# M2003 register map
File version: 1.0
Registers are 32-bit, read-write, reset 0x0 unless marked. A register's access mark holds for its fields unless they carry their own. Offsets are from the block's base; [hi:lo] are bit positions; {n}, {i} and the like mark numbered series; 'fields as' and 'values as' point back to an identical list.

## ECAP0 — ECAP Register Map
Base 0x400B4000
0x00 ECAP_CNT — Input Capture Counter (24-bit Up Counter)
  [23:0] CNT — Input Capture Timer/Counter. The input Capture Timer/Counter is a 24-bit up-counting counter. The clock source for the counter is from the clock divider.
{0x4+4i} ECAP_HLD{i} (i=0..2) — Input Capture Hold Register {i}
  [23:0] HOLD — Input Capture Counter Hold Register. When an active input capture channel detects a valid edge signal change, the ECAPCNT value is latched into the corresponding holding register. Each input channel has its own holding register named by ECAP_HLDx where x is from 0 to 2 to indicate inputs from IC0 to IC2, respectively.
0x10 ECAP_CNTCMP — Input Capture Compare Register
  [23:0] CNTCMP — Input Capture Counter Compare Register
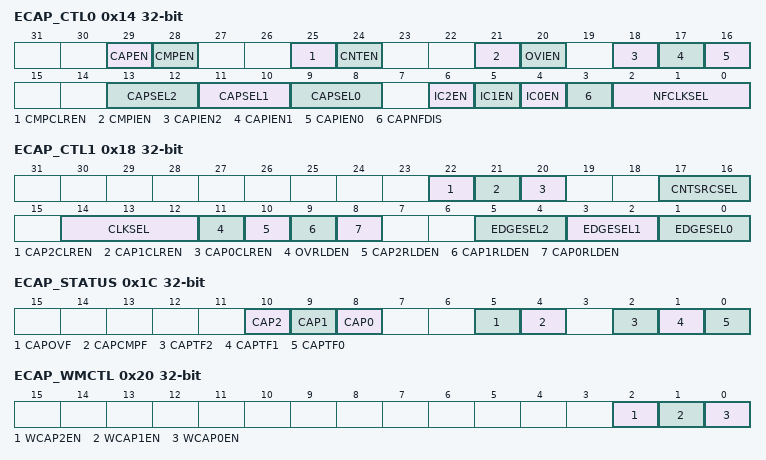
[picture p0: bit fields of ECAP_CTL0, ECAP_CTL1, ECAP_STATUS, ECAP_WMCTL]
0x14 ECAP_CTL0 — Input Capture Control Register 0
  [29] CAPEN — Input Capture Timer/Counter Enable Bit
    0=Input Capture function Disabled; 1=Input Capture function Enabled
  [28] CMPEN — Compare Function Enable Bit. The compare function in input capture timer/counter is to compare the dynamic counting ECAP_CNT with the compare register ECAP_CNTCMP, if ECAP_CNT value reaches ECAP_CNTCMP, the flag CAPCMPF will be set.
    0=The compare function Disabled; 1=The compare function Enabled
  [25] CMPCLREN — Input Capture Counter Cleared by Compare-match Control
    0=Compare-match event (CAPCMPF) can clear capture counter (ECAP_CNT) Disabled; 1=Compare-match event (CAPCMPF) can clear capture counter (ECAP_CNT) Enabled
  [24] CNTEN — Input Capture Counter Start Counting Control. Setting this bit to 1, the capture counter (ECAP_CNT) starts up-counting the clock.
    0=ECAP_CNT stops counting; 1=ECAP_CNT starts up-counting
  [21] CMPIEN — CAPCMPF Trigger Input Capture Interrupt Enable Bit
    0=The flag CAPCMPF can trigger Input Capture interrupt Disabled; 1=The flag CAPCMPF can trigger Input Capture interrupt Enabled
  [20] OVIEN — CAPOVF Trigger Input Capture Interrupt Enable Bit
    0=The flag CAPOVF can trigger Input Capture interrupt Disabled; 1=The flag CAPOVF can trigger Input Capture interrupt Enabled
  [18] CAPIEN2 — Input Capture Channel 2 Interrupt Enable Control
    0=The flag CAPTF2 can trigger Input Capture interrupt Disabled; 1=The flag CAPTF2 can trigger Input Capture interrupt Enabled
  [17] CAPIEN1 — Input Capture Channel 1 Interrupt Enable Control
    0=The flag CAPTF1 can trigger Input Capture interrupt Disabled; 1=The flag CAPTF1 can trigger Input Capture interrupt Enabled
  [16] CAPIEN0 — Input Capture Channel 0 Interrupt Enable Control
    0=The flag CAPTF0 can trigger Input Capture interrupt Disabled; 1=The flag CAPTF0 can trigger Input Capture interrupt Enabled
  [13:12] CAPSEL2 — CAP2 Input Source Selection
    0=CAP2 input is from port pin ICAP2
  [11:10] CAPSEL1 — CAP1 Input Source Selection
    0=CAP1 input is from port pin ICAP1
  [9:8] CAPSEL0 — CAP0 Input Source Selection
    0=CAP0 input is from port pin ICAP0
  [6] IC2EN — Port Pin IC2 Input to Input Capture Unit Enable Control
    0=IC2 input to Input Capture Unit Disabled; 1=IC2 input to Input Capture Unit Enabled
  [5] IC1EN — Port Pin IC1 Input to Input Capture Unit Enable Control
    0=IC1 input to Input Capture Unit Disabled; 1=IC1 input to Input Capture Unit Enabled
  [4] IC0EN — Port Pin IC0 Input to Input Capture Unit Enable Control
    0=IC0 input to Input Capture Unit Disabled; 1=IC0 input to Input Capture Unit Enabled
  [3] CAPNFDIS — Input Capture Noise Filter Disable Control
    0=Noise filter of Input Capture Enabled; 1=Noise filter of Input Capture Disabled (Bypass)
  [2:0] NFCLKSEL — Noise Filter Clock Pre-divide Selection. To determine the sampling frequency of the Noise Filter clock
    0=CAP_CLK; 1=CAP_CLK/2; 2=CAP_CLK/4; 3=CAP_CLK/16; 4=CAP_CLK/32; 5=CAP_CLK/64
0x18 ECAP_CTL1 — Input Capture Control Register 1
  [22] CAP2CLREN — Capture Counter Cleared by Capture Event2 Control
    0=Event CAPTE2 can clear capture counter (ECAP_CNT) Disabled; 1=Event CAPTE2 can clear capture counter (ECAP_CNT) Enabled
  [21] CAP1CLREN — Capture Counter Cleared by Capture Event1 Control
    0=Event CAPTE1 can clear capture counter (ECAP_CNT) Disabled; 1=Event CAPTE1 can clear capture counter (ECAP_CNT) Enabled
  [20] CAP0CLREN — Capture Counter Cleared by Capture Event0 Control
    0=Event CAPTE0 can clear capture counter (ECAP_CNT) Disabled; 1=Event CAPTE0 can clear capture counter (ECAP_CNT) Enabled
  [17:16] CNTSRCSEL — Capture Timer/Counter Clock Source Selection. Select the capture timer/counter clock source.
    0=CAP_CLK (default); 1=CAP0; 2=CAP1; 3=CAP2
  [14:12] CLKSEL — Capture Timer Clock Divide Selection. The capture timer clock has a pre-divider with eight divided options controlled by CLKSEL[2:0].
    0=CAP_CLK/1; 1=CAP_CLK/4; 2=CAP_CLK/16; 3=CAP_CLK/32; 4=CAP_CLK/64; 5=CAP_CLK/96; 6=CAP_CLK/112; 7=CAP_CLK/128
  [11] OVRLDEN — Capture Counter's Reload Function Triggered by Overflow Enable Bit
    0=The reload triggered by CAPOV Disabled; 1=The reload triggered by CAPOV Enabled
  [10] CAP2RLDEN — Capture Counter's Reload Function Triggered by Event CAPTE2 Enable Bit
    0=The reload triggered by Event CAPTE2 Disabled; 1=The reload triggered by Event CAPTE2 Enabled
  [9] CAP1RLDEN — Capture Counter's Reload Function Triggered by Event CAPTE1 Enable Bit
    0=The reload triggered by Event CAPTE1 Disabled; 1=The reload triggered by Event CAPTE1 Enabled
  [8] CAP0RLDEN — Capture Counter's Reload Function Triggered by Event CAPTE0 Enable Bit
    0=The reload triggered by Event CAPTE0 Disabled; 1=The reload triggered by Event CAPTE0 Enabled
  [5:4] EDGESEL2 — Channel 2 Captured Edge Selection. Input capture2 can detect falling edge change only, rising edge change only or both edge changes
    0=Detect rising edge only; 1=Detect falling edge only. Detect both rising and falling edge
  [3:2] EDGESEL1 — Channel 1 Captured Edge Selection. Input capture1 can detect falling edge change only, rising edge change only or both edge change
    values as EDGESEL2
  [1:0] EDGESEL0 — Channel 0 Captured Edge Selection. Input capture0 can detect falling edge change only, rising edge change only or both edge change
    values as EDGESEL2
0x1C ECAP_STATUS — Input Capture Status Register
  [10] CAP2 ro — Value of Input Channel 2, CAP2 (Read Only). Reflecting the value of input channel 2, CAP2. Note: The bit is read only and write is ignored.
  [9] CAP1 ro — Value of Input Channel 1, CAP1 (Read Only). Reflecting the value of input channel 1, CAP1. Note: The bit is read only and write is ignored.
  [8] CAP0 ro — Value of Input Channel 0, CAP0 (Read Only). Reflecting the value of input channel 0, CAP0. Note: The bit is read only and write is ignored.
  [5] CAPOVF — Input Capture Counter Overflow Flag. Flag is set by hardware when counter (ECAP_CNT) overflows from 0x00FF_FFFF to zero. Note: This bit is only cleared by writing 1 to it.
    0=No overflow event has occurred since last clear; 1=Overflow event(s) has/have occurred since last clear
  [4] CAPCMPF — Input Capture Compare-match Flag. If the input capture compare function is enabled, the flag is set by hardware when capture counter (ECAP_CNT) up counts and reaches the ECAP_CNTCMP value. Note: This bit is only cleared by writing 1 to it.
    0=ECAP_CNT has not matched ECAP_CNTCMP value since last clear; 1=ECAP_CNT has matched ECAP_CNTCMP value at least once since last clear
  [2] CAPTF2 — Input Capture Channel 2 Triggered Flag. When the input capture channel 2 detects a valid edge change at CAP2 input, it will set flag CAPTF2 to high. Note: This bit is only cleared by writing 1 to it.
    0=No valid edge change has been detected at CAP2 input since last clear; 1=At least a valid edge change has been detected at CAP2 input since last clear
  [1] CAPTF1 — Input Capture Channel 1 Triggered Flag. When the input capture channel 1 detects a valid edge change at CAP1 input, it will set flag CAPTF1 to high. Note: This bit is only cleared by writing 1 to it.
    0=No valid edge change has been detected at CAP1 input since last clear; 1=At least a valid edge change has been detected at CAP1 input since last clear
  [0] CAPTF0 — Input Capture Channel 0 Triggered Flag. When the input capture channel 0 detects a valid edge change at CAP0 input, it will set flag CAPTF0 to high. Note: This bit is only cleared by writing 1 to it.
    0=No valid edge change has been detected at CAP0 input since last clear; 1=At least a valid edge change has been detected at CAP0 input since last clear
0x20 ECAP_WMCTL — Input Capture timer/Counter Window Mode Control Register
  [2] WCAP2EN — Window Mode CAP2 Enable Bit
    0=CAP2 Window Mode is Disabled; 1=CAP2 Window Mode is Enabled
  [1] WCAP1EN — Window Mode CAP1 Enable Bit
    0=CAP1 Window Mode is Disabled; 1=CAP1 Window Mode is Enabled
  [0] WCAP0EN — Window Mode CAP0 Enable Bit
    0=CAP0 Window Mode is Disabled; 1=CAP0 Window Mode is Enabled
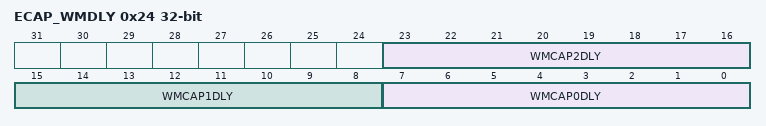
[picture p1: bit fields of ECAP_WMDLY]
0x24 ECAP_WMDLY — Window Mode CAP Trigger Delay Control Register
  [23:16] WMCAP2DLY — Window Mode CAP2 Delay Timer. Setting this field will delay CAP2 window period after WM CAP2 trigger is coming. Delay time is (4 * WMCAP2DLY) * ECAP_CLK
  [15:8] WMCAP1DLY — Window Mode CAP1 Delay Timer. Setting this field will delay CAP1 window period after WM CAP1 trigger is coming. Delay time is (4 * WMCAP1DLY) * ECAP_CLK
  [7:0] WMCAP0DLY — Window Mode CAP0 Delay Timer. Setting this field will delay CAP0 window period after WM CAP0 trigger is coming. Delay time is (4 * WMCAP0DLY) * ECAP_CLK
0x28 ECAP_TRGHLD — Window Mode Trigger Counter Hold Register
  [23:0] TRGHOLD — Window Mode Trigger Counter Hold Register. When WM CAP0 trigger is coming, the ECAPCNT value is latched into this holding register.
